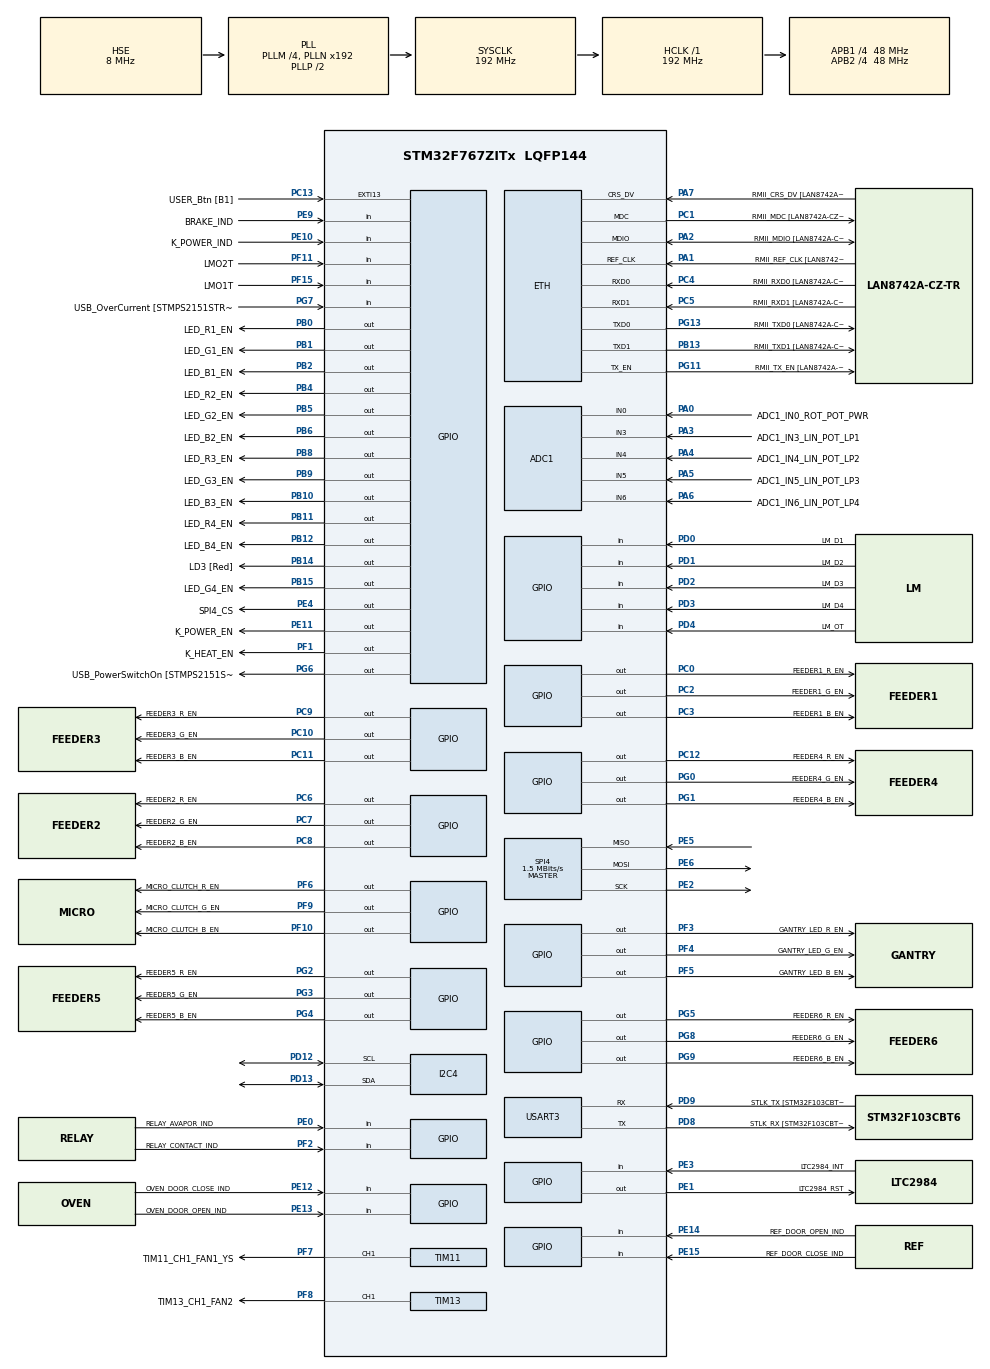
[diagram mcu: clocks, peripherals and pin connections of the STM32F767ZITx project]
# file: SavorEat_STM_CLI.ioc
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ADC1.Channel-0\#ChannelRegularConversion=ADC_CHANNEL_0
ADC1.NbrOfConversionFlag=1
ADC1.Rank-0\#ChannelRegularConversion=1
ADC1.SamplingTime-0\#ChannelRegularConversion=ADC_SAMPLETIME_112CYCLES
ADC1.master=1
ETH.MediaInterface=HAL_ETH_RMII_MODE
ETH.PHY_Name=LAN8742A_PHY_ADDRESS
ETH.PHY_Value=0
ETH.PhyAddress=0
FREERTOS.Tasks01=defaultTask,0,2048,StartDefaultTask,Default,NULL,Dynamic,NULL,NULL
FREERTOS.configTOTAL_HEAP_SIZE=0x20000
FREERTOS.configUSE_NEWLIB_REENTRANT=1
I2C4.Timing=0x20303E5D
LWIP.BSP.number=1
LWIP.GATEWAY_ADDRESS=010.001.001.001
LWIP.IP_ADDRESS=010.001.001.020
LWIP.LWIP_DHCP=0
LWIP.LWIP_MPU_COMPATIBLE=0
LWIP.NETMASK_ADDRESS=255.255.255.000
LWIP.Version=v2.1.2_Cube
LWIP0.BSP.STBoard=false
LWIP0.BSP.api=BSP_COMPONENT_DRIVER
LWIP0.BSP.component=LAN8742
LWIP0.BSP.instance=LAN8742
LWIP0.BSP.name=Driver_PHY
LWIP0.BSP.semaphore=S_LAN8742
LWIP0.BSP.solution=LAN8742
Mcu.Family=STM32F7
Mcu.Name=STM32F767ZITx
Mcu.Package=LQFP144
NVIC.ETH_IRQn=true\:5\:0\:false\:false\:true\:true\:false\:true\:true
NVIC.EXTI15_10_IRQn=true\:5\:0\:false\:false\:true\:true\:true\:true\:true
NVIC.PriorityGroup=NVIC_PRIORITYGROUP_4
NVIC.TIM1_UP_TIM10_IRQn=true\:15\:0\:false\:false\:true\:false\:false\:true\:true
NVIC.TimeBase=TIM1_UP_TIM10_IRQn
NVIC.TimeBaseIP=TIM10
PA0/WKUP.GPIO_Label=ADC1_IN0_ROT_POT_PWR
PA0/WKUP.Signal=ADCx_IN0
PA1.GPIO_Label=RMII_REF_CLK [LAN8742A-CZ-TR_REFCLK0]
PA1.Mode=RMII
PA1.Signal=ETH_REF_CLK
PA10.GPIO_Label=USB_ID
PA10.Signal=USB_OTG_FS_ID
PA11.GPIO_Label=USB_DM
PA11.Signal=USB_OTG_FS_DM
PA12.GPIO_Label=USB_DP
PA12.Signal=USB_OTG_FS_DP
PA13.GPIO_Label=TMS
PA13.Mode=Trace_Asynchronous_SW
PA13.Signal=SYS_JTMS-SWDIO
PA14.GPIO_Label=TCK
PA14.Mode=Trace_Asynchronous_SW
PA14.Signal=SYS_JTCK-SWCLK
PA2.GPIO_Label=RMII_MDIO [LAN8742A-CZ-TR_MDIO]
PA2.Mode=RMII
PA2.Signal=ETH_MDIO
PA3.GPIO_Label=ADC1_IN3_LIN_POT_LP1
PA3.Signal=ADCx_IN3
PA4.GPIO_Label=ADC1_IN4_LIN_POT_LP2
PA4.Signal=ADCx_IN4
PA5.GPIO_Label=ADC1_IN5_LIN_POT_LP3
PA5.Signal=ADCx_IN5
PA6.GPIO_Label=ADC1_IN6_LIN_POT_LP4
PA6.Signal=ADCx_IN6
PA7.GPIO_Label=RMII_CRS_DV [LAN8742A-CZ-TR_CRS_DV]
PA7.Mode=RMII
PA7.Signal=ETH_CRS_DV
PA8.GPIO_Label=USB_SOF [TP1]
PA8.Signal=USB_OTG_FS_SOF
PA9.GPIO_Label=USB_VBUS
PA9.Signal=USB_OTG_FS_VBUS
PB0.GPIO_Label=LED_R1_EN
PB0.Signal=GPIO_Output
PB1.GPIO_Label=LED_G1_EN
PB1.Signal=GPIO_Output
PB10.GPIO_Label=LED_B3_EN
PB10.Signal=GPIO_Output
PB11.GPIO_Label=LED_R4_EN
PB11.Signal=GPIO_Output
PB12.GPIO_Label=LED_B4_EN
PB12.Signal=GPIO_Output
PB13.GPIO_Label=RMII_TXD1 [LAN8742A-CZ-TR_TXD1]
PB13.Mode=RMII
PB13.Signal=ETH_TXD1
PB14.GPIO_Label=LD3 [Red]
PB14.Signal=GPIO_Output
PB15.GPIO_Label=LED_G4_EN
PB15.Signal=GPIO_Output
PB2.GPIO_Label=LED_B1_EN
PB2.Signal=GPIO_Output
PB3.GPIO_Label=SWO
PB3.Mode=Trace_Asynchronous_SW
PB3.Signal=SYS_JTDO-SWO
PB4.GPIO_Label=LED_R2_EN
PB4.Signal=GPIO_Output
PB5.GPIO_Label=LED_G2_EN
PB5.Signal=GPIO_Output
PB6.GPIO_Label=LED_B2_EN
PB6.Signal=GPIO_Output
PB8.GPIO_Label=LED_R3_EN
PB8.Signal=GPIO_Output
PB9.GPIO_Label=LED_G3_EN
PB9.Signal=GPIO_Output
PC0.GPIO_Label=FEEDER1_R_EN
PC0.Signal=GPIO_Output
PC1.GPIO_Label=RMII_MDC [LAN8742A-CZ-TR_MDC]
PC1.Mode=RMII
PC1.Signal=ETH_MDC
PC10.GPIO_Label=FEEDER3_G_EN
PC10.Signal=GPIO_Output
PC11.GPIO_Label=FEEDER3_B_EN
PC11.Signal=GPIO_Output
PC12.GPIO_Label=FEEDER4_R_EN
PC12.Signal=GPIO_Output
PC13.GPIO_Label=USER_Btn [B1]
PC13.Signal=GPXTI13
PC14/OSC32_IN.Mode=LSE-External-Oscillator
PC14/OSC32_IN.Signal=RCC_OSC32_IN
PC15/OSC32_OUT.Mode=LSE-External-Oscillator
PC15/OSC32_OUT.Signal=RCC_OSC32_OUT
PC2.GPIO_Label=FEEDER1_G_EN
PC2.Signal=GPIO_Output
PC3.GPIO_Label=FEEDER1_B_EN
PC3.Signal=GPIO_Output
PC4.GPIO_Label=RMII_RXD0 [LAN8742A-CZ-TR_RXD0]
PC4.Mode=RMII
PC4.Signal=ETH_RXD0
PC5.GPIO_Label=RMII_RXD1 [LAN8742A-CZ-TR_RXD1]
PC5.Mode=RMII
PC5.Signal=ETH_RXD1
PC6.GPIO_Label=FEEDER2_R_EN
PC6.Signal=GPIO_Output
PC7.GPIO_Label=FEEDER2_G_EN
PC7.Signal=GPIO_Output
PC8.GPIO_Label=FEEDER2_B_EN
PC8.Signal=GPIO_Output
PC9.GPIO_Label=FEEDER3_R_EN
PC9.Signal=GPIO_Output
PD0.GPIO_Label=LM_D1
PD0.Signal=GPIO_Input
PD1.GPIO_Label=LM_D2
PD1.Signal=GPIO_Input
PD12.Mode=I2C
PD12.Signal=I2C4_SCL
PD13.Mode=I2C
PD13.Signal=I2C4_SDA
PD2.GPIO_Label=LM_D3
PD2.Signal=GPIO_Input
PD3.GPIO_Label=LM_D4
PD3.Signal=GPIO_Input
PD4.GPIO_Label=LM_OT
PD4.Signal=GPIO_Input
PD8.GPIO_Label=STLK_RX [STM32F103CBT6_PA3]
PD8.Mode=Asynchronous
PD8.Signal=USART3_TX
PD9.GPIO_Label=STLK_TX [STM32F103CBT6_PA2]
PD9.Mode=Asynchronous
PD9.Signal=USART3_RX
PE0.GPIO_Label=RELAY_AVAPOR_IND
PE0.Signal=GPIO_Input
PE1.GPIO_Label=LTC2984_RST
PE1.PinState=GPIO_PIN_SET
PE1.Signal=GPIO_Output
PE10.GPIO_Label=K_POWER_IND
PE10.Signal=GPIO_Input
PE11.GPIO_Label=K_POWER_EN
PE11.Signal=GPIO_Output
PE12.GPIO_Label=OVEN_DOOR_CLOSE_IND
PE12.Signal=GPIO_Input
PE13.GPIO_Label=OVEN_DOOR_OPEN_IND
PE13.Signal=GPIO_Input
PE14.GPIO_Label=REF_DOOR_OPEN_IND
PE14.Signal=GPIO_Input
PE15.GPIO_Label=REF_DOOR_CLOSE_IND
PE15.Signal=GPIO_Input
PE2.Mode=Full_Duplex_Master
PE2.Signal=SPI4_SCK
PE3.GPIO_Label=LTC2984_INT
PE3.Signal=GPIO_Input
PE4.GPIO_Label=SPI4_CS
PE4.GPIO_Speed=GPIO_SPEED_FREQ_VERY_HIGH
PE4.PinState=GPIO_PIN_SET
PE4.Signal=GPIO_Output
PE5.Mode=Full_Duplex_Master
PE5.Signal=SPI4_MISO
PE6.Mode=Full_Duplex_Master
PE6.Signal=SPI4_MOSI
PE9.GPIO_Label=BRAKE_IND
PE9.Signal=GPIO_Input
PF1.GPIO_Label=K_HEAT_EN
PF1.Signal=GPIO_Output
PF10.GPIO_Label=MICRO_CLUTCH_B_EN
PF10.Signal=GPIO_Output
PF11.GPIO_Label=LMO2T
PF11.Signal=GPIO_Input
PF15.GPIO_Label=LMO1T
PF15.Signal=GPIO_Input
PF2.GPIO_Label=RELAY_CONTACT_IND
PF2.Signal=GPIO_Input
PF3.GPIO_Label=GANTRY_LED_R_EN
PF3.Signal=GPIO_Output
PF4.GPIO_Label=GANTRY_LED_G_EN
PF4.Signal=GPIO_Output
PF5.GPIO_Label=GANTRY_LED_B_EN
PF5.Signal=GPIO_Output
PF6.GPIO_Label=MICRO_CLUTCH_R_EN
PF6.Signal=GPIO_Output
PF7.GPIO_Label=TIM11_CH1_FAN1_YS
PF7.Signal=S_TIM11_CH1
PF8.GPIO_Label=TIM13_CH1_FAN2
PF8.Signal=S_TIM13_CH1
PF9.GPIO_Label=MICRO_CLUTCH_G_EN
PF9.Signal=GPIO_Output
PG0.GPIO_Label=FEEDER4_G_EN
PG0.Signal=GPIO_Output
PG1.GPIO_Label=FEEDER4_B_EN
PG1.Signal=GPIO_Output
PG11.GPIO_Label=RMII_TX_EN [LAN8742A-CZ-TR_TXEN]
PG11.Mode=RMII
PG11.Signal=ETH_TX_EN
PG13.GPIO_Label=RMII_TXD0 [LAN8742A-CZ-TR_TXD0]
PG13.Mode=RMII
PG13.Signal=ETH_TXD0
PG2.GPIO_Label=FEEDER5_R_EN
PG2.Signal=GPIO_Output
PG3.GPIO_Label=FEEDER5_G_EN
PG3.Signal=GPIO_Output
PG4.GPIO_Label=FEEDER5_B_EN
PG4.Signal=GPIO_Output
PG5.GPIO_Label=FEEDER6_R_EN
PG5.Signal=GPIO_Output
PG6.GPIO_Label=USB_PowerSwitchOn [STMPS2151STR_EN]
PG6.Signal=GPIO_Output
PG7.GPIO_Label=USB_OverCurrent [STMPS2151STR_FAULT]
PG7.Signal=GPIO_Input
PG8.GPIO_Label=FEEDER6_G_EN
PG8.Signal=GPIO_Output
PG9.GPIO_Label=FEEDER6_B_EN 
PG9.Signal=GPIO_Output
PH0/OSC_IN.GPIO_Label=MCO [STM32F103CBT6_PA8]
PH0/OSC_IN.Mode=HSE-External-Oscillator
PH0/OSC_IN.Signal=RCC_OSC_IN
PH1/OSC_OUT.Mode=HSE-External-Oscillator
PH1/OSC_OUT.Signal=RCC_OSC_OUT
ProjectManager.HeapSize=0x200
ProjectManager.StackSize=0x400
ProjectManager.TargetToolchain=STM32CubeIDE
RCC.48MHZClocksFreq_Value=24000000
RCC.AHBFreq_Value=192000000
RCC.APB1CLKDivider=RCC_HCLK_DIV4
RCC.APB1Freq_Value=48000000
RCC.APB1TimFreq_Value=96000000
RCC.APB2CLKDivider=RCC_HCLK_DIV4
RCC.APB2Freq_Value=48000000
RCC.APB2TimFreq_Value=96000000
RCC.CortexFreq_Value=192000000
RCC.HCLKFreq_Value=192000000
RCC.HSE_VALUE=8000000
RCC.HSI_VALUE=16000000
RCC.PLLM=4
RCC.PLLMUL=RCC_PLL_MUL9
RCC.PLLQ=8
RCC.PLLSourceVirtual=RCC_PLLSOURCE_HSE
RCC.PRESCALERUSB=RCC_USBCLKSOURCE_PLL_DIV1_5
RCC.SYSCLKFreq_VALUE=192000000
RCC.SYSCLKSource=RCC_SYSCLKSOURCE_PLLCLK
RCC.SYSCLKSourceVirtual=RCC_SYSCLKSOURCE_PLLCLK
RCC.USBFreq_Value=48000000
RCC.VCOOutputFreq_Value=384000000
SH.ADCx_IN0.0=ADC1_IN0,IN0
SH.ADCx_IN3.0=ADC1_IN3,IN3
SH.ADCx_IN4.0=ADC1_IN4,IN4
SH.ADCx_IN5.0=ADC1_IN5,IN5
SH.ADCx_IN6.0=ADC1_IN6,IN6
SH.S_TIM11_CH1.0=TIM11_CH1,PWM Generation1 CH1
SH.S_TIM13_CH1.0=TIM13_CH1,PWM Generation1 CH1
SPI4.BaudRatePrescaler=SPI_BAUDRATEPRESCALER_32
SPI4.CLKPolarity=SPI_POLARITY_LOW
SPI4.CalculateBaudRate=1.5 MBits/s
SPI4.DataSize=SPI_DATASIZE_8BIT
SPI4.Direction=SPI_DIRECTION_2LINES
SPI4.Mode=SPI_MODE_MASTER
SPI4.VirtualType=VM_MASTER
TIM11.AutoReloadPreload=TIM_AUTORELOAD_PRELOAD_ENABLE
TIM11.Channel=TIM_CHANNEL_1
TIM11.Period=100-1
TIM11.Prescaler=40-1
TIM11.Pulse=20
TIM13.AutoReloadPreload=TIM_AUTORELOAD_PRELOAD_ENABLE
TIM13.Channel=TIM_CHANNEL_1
TIM13.Period=100-1
TIM13.Prescaler=9600-1
TIM13.Pulse=20
USART3.VirtualMode-Asynchronous=VM_ASYNC
VP_FREERTOS_VS_CMSIS_V1.Mode=CMSIS_V1
VP_LWIP_VS_Enabled.Mode=Enabled
VP_SYS_VS_tim10.Mode=TIM10
VP_TIM11_VS_ClockSourceINT.Mode=Enable_Timer
VP_TIM13_VS_ClockSourceINT.Mode=Enable_Timer
board=NUCLEO-F767ZI

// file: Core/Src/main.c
/* USER CODE BEGIN Header */
/**
  ******************************************************************************
  * @file           : main.c
  * @brief          : Main program body
  ******************************************************************************
  * @attention
  *
  * Copyright (c) 2023 STMicroelectronics.
  * All rights reserved.
  *
  * This software is licensed under terms that can be found in the LICENSE file
  * in the root directory of this software component.
  * If no LICENSE file comes with this software, it is provided AS-IS.
  *
  ******************************************************************************
  */
/* USER CODE END Header */
#include "main.h"
#include "cmsis_os.h"
#include "lwip.h"

/* USER CODE BEGIN Includes */
#include <stdio.h>
#include "Utils.h"
#include "Main_Task_Mgr.h"
#include "Syslog_Mgr.h"
#include "CLI_Mgr.h"
/* USER CODE END Includes */

ADC_HandleTypeDef hadc1;

I2C_HandleTypeDef hi2c4;

SPI_HandleTypeDef hspi4;

TIM_HandleTypeDef htim11;
TIM_HandleTypeDef htim13;

UART_HandleTypeDef huart3;

osThreadId defaultTaskHandle;

void SystemClock_Config(void);
static void MX_GPIO_Init(void);
static void MX_USART3_UART_Init(void);
static void MX_ADC1_Init(void);
static void MX_I2C4_Init(void);
static void MX_SPI4_Init(void);
static void MX_TIM11_Init(void);
static void MX_TIM13_Init(void);
void StartDefaultTask(void const * argument);

int main(void)
{

  /* MCU Configuration--------------------------------------------------------*/

  /* Reset of all peripherals, Initializes the Flash interface and the Systick. */
  HAL_Init();

  /* Configure the system clock */
  SystemClock_Config();

  /* Initialize all configured peripherals */
  MX_GPIO_Init();
  MX_USART3_UART_Init();
  MX_ADC1_Init();
  MX_I2C4_Init();
  MX_SPI4_Init();
  MX_TIM11_Init();
  MX_TIM13_Init();

  /* USER CODE BEGIN RTOS_QUEUES */
  /* add queues, ... */
  if( Main_Task_Mgr_Syslog_Queue_Init() )
  {
  	  //TBD error
  }

  /* USER CODE END RTOS_QUEUES */

  /* Create the thread(s) */
  /* definition and creation of defaultTask */
  osThreadDef(defaultTask, StartDefaultTask, osPriorityNormal, 0, 2048);
  defaultTaskHandle = osThreadCreate(osThread(defaultTask), NULL);

  /* USER CODE BEGIN RTOS_THREADS */
  /* add threads, ... */
  if( Syslog_Mgr_Thread_Init() )
  {
	  //TBD Error
  }

  /* USER CODE END RTOS_THREADS */

  /* Start scheduler */
  osKernelStart();

  /* We should never get here as control is now taken by the scheduler */
  /* Infinite loop */
  while (1)
  {

  }
}

void SystemClock_Config(void)
{
  RCC_OscInitTypeDef RCC_OscInitStruct = {0};
  RCC_ClkInitTypeDef RCC_ClkInitStruct = {0};

  /** Configure LSE Drive Capability
  */
  HAL_PWR_EnableBkUpAccess();

  /** Configure the main internal regulator output voltage
  */
  __HAL_RCC_PWR_CLK_ENABLE();
  __HAL_PWR_VOLTAGESCALING_CONFIG(PWR_REGULATOR_VOLTAGE_SCALE1);

  /** Initializes the RCC Oscillators according to the specified parameters
  * in the RCC_OscInitTypeDef structure.
  */
  RCC_OscInitStruct.OscillatorType = RCC_OSCILLATORTYPE_HSE;
  RCC_OscInitStruct.HSEState = RCC_HSE_ON;
  RCC_OscInitStruct.PLL.PLLState = RCC_PLL_ON;
  RCC_OscInitStruct.PLL.PLLSource = RCC_PLLSOURCE_HSE;
  RCC_OscInitStruct.PLL.PLLM = 4;
  RCC_OscInitStruct.PLL.PLLN = 192;
  RCC_OscInitStruct.PLL.PLLP = RCC_PLLP_DIV2;
  RCC_OscInitStruct.PLL.PLLQ = 8;
  RCC_OscInitStruct.PLL.PLLR = 2;
  if (HAL_RCC_OscConfig(&RCC_OscInitStruct) != HAL_OK)
  {
    Error_Handler();
  }

  /** Activate the Over-Drive mode
  */
  if (HAL_PWREx_EnableOverDrive() != HAL_OK)
  {
    Error_Handler();
  }

  /** Initializes the CPU, AHB and APB buses clocks
  */
  RCC_ClkInitStruct.ClockType = RCC_CLOCKTYPE_HCLK|RCC_CLOCKTYPE_SYSCLK
                              |RCC_CLOCKTYPE_PCLK1|RCC_CLOCKTYPE_PCLK2;
  RCC_ClkInitStruct.SYSCLKSource = RCC_SYSCLKSOURCE_PLLCLK;
  RCC_ClkInitStruct.AHBCLKDivider = RCC_SYSCLK_DIV1;
  RCC_ClkInitStruct.APB1CLKDivider = RCC_HCLK_DIV4;
  RCC_ClkInitStruct.APB2CLKDivider = RCC_HCLK_DIV4;

  if (HAL_RCC_ClockConfig(&RCC_ClkInitStruct, FLASH_LATENCY_6) != HAL_OK)
  {
    Error_Handler();
  }
}

static void MX_ADC1_Init(void)
{

  ADC_ChannelConfTypeDef sConfig = {0};

  /** Configure the global features of the ADC (Clock, Resolution, Data Alignment and number of conversion)
  */
  hadc1.Instance = ADC1;
  hadc1.Init.ClockPrescaler = ADC_CLOCK_SYNC_PCLK_DIV2;
  hadc1.Init.Resolution = ADC_RESOLUTION_12B;
  hadc1.Init.ScanConvMode = ADC_SCAN_DISABLE;
  hadc1.Init.ContinuousConvMode = DISABLE;
  hadc1.Init.DiscontinuousConvMode = DISABLE;
  hadc1.Init.ExternalTrigConvEdge = ADC_EXTERNALTRIGCONVEDGE_NONE;
  hadc1.Init.ExternalTrigConv = ADC_SOFTWARE_START;
  hadc1.Init.DataAlign = ADC_DATAALIGN_RIGHT;
  hadc1.Init.NbrOfConversion = 1;
  hadc1.Init.DMAContinuousRequests = DISABLE;
  hadc1.Init.EOCSelection = ADC_EOC_SINGLE_CONV;
  if (HAL_ADC_Init(&hadc1) != HAL_OK)
  {
    Error_Handler();
  }

  /** Configure for the selected ADC regular channel its corresponding rank in the sequencer and its sample time.
  */
  sConfig.Channel = ADC_CHANNEL_0;
  sConfig.Rank = ADC_REGULAR_RANK_1;
  sConfig.SamplingTime = ADC_SAMPLETIME_112CYCLES;
  if (HAL_ADC_ConfigChannel(&hadc1, &sConfig) != HAL_OK)
  {
    Error_Handler();
  }

}

static void MX_I2C4_Init(void)
{

  hi2c4.Instance = I2C4;
  hi2c4.Init.Timing = 0x20303E5D;
  hi2c4.Init.OwnAddress1 = 0;
  hi2c4.Init.AddressingMode = I2C_ADDRESSINGMODE_7BIT;
  hi2c4.Init.DualAddressMode = I2C_DUALADDRESS_DISABLE;
  hi2c4.Init.OwnAddress2 = 0;
  hi2c4.Init.OwnAddress2Masks = I2C_OA2_NOMASK;
  hi2c4.Init.GeneralCallMode = I2C_GENERALCALL_DISABLE;
  hi2c4.Init.NoStretchMode = I2C_NOSTRETCH_DISABLE;
  if (HAL_I2C_Init(&hi2c4) != HAL_OK)
  {
    Error_Handler();
  }

  /** Configure Analogue filter
  */
  if (HAL_I2CEx_ConfigAnalogFilter(&hi2c4, I2C_ANALOGFILTER_ENABLE) != HAL_OK)
  {
    Error_Handler();
  }

  /** Configure Digital filter
  */
  if (HAL_I2CEx_ConfigDigitalFilter(&hi2c4, 0) != HAL_OK)
  {
    Error_Handler();
  }

}

static void MX_SPI4_Init(void)
{

  /* SPI4 parameter configuration*/
  hspi4.Instance = SPI4;
  hspi4.Init.Mode = SPI_MODE_MASTER;
  hspi4.Init.Direction = SPI_DIRECTION_2LINES;
  hspi4.Init.DataSize = SPI_DATASIZE_8BIT;
  hspi4.Init.CLKPolarity = SPI_POLARITY_LOW;
  hspi4.Init.CLKPhase = SPI_PHASE_1EDGE;
  hspi4.Init.NSS = SPI_NSS_SOFT;
  hspi4.Init.BaudRatePrescaler = SPI_BAUDRATEPRESCALER_32;
  hspi4.Init.FirstBit = SPI_FIRSTBIT_MSB;
  hspi4.Init.TIMode = SPI_TIMODE_DISABLE;
  hspi4.Init.CRCCalculation = SPI_CRCCALCULATION_DISABLE;
  hspi4.Init.CRCPolynomial = 7;
  hspi4.Init.CRCLength = SPI_CRC_LENGTH_DATASIZE;
  hspi4.Init.NSSPMode = SPI_NSS_PULSE_ENABLE;
  if (HAL_SPI_Init(&hspi4) != HAL_OK)
  {
    Error_Handler();
  }

}

static void MX_TIM11_Init(void)
{

  TIM_OC_InitTypeDef sConfigOC = {0};

  htim11.Instance = TIM11;
  htim11.Init.Prescaler = 40-1;
  htim11.Init.CounterMode = TIM_COUNTERMODE_UP;
  htim11.Init.Period = 100-1;
  htim11.Init.ClockDivision = TIM_CLOCKDIVISION_DIV1;
  htim11.Init.AutoReloadPreload = TIM_AUTORELOAD_PRELOAD_ENABLE;
  if (HAL_TIM_Base_Init(&htim11) != HAL_OK)
  {
    Error_Handler();
  }
  if (HAL_TIM_PWM_Init(&htim11) != HAL_OK)
  {
    Error_Handler();
  }
  sConfigOC.OCMode = TIM_OCMODE_PWM1;
  sConfigOC.Pulse = 20;
  sConfigOC.OCPolarity = TIM_OCPOLARITY_HIGH;
  sConfigOC.OCFastMode = TIM_OCFAST_DISABLE;
  if (HAL_TIM_PWM_ConfigChannel(&htim11, &sConfigOC, TIM_CHANNEL_1) != HAL_OK)
  {
    Error_Handler();
  }
  HAL_TIM_MspPostInit(&htim11);

}

static void MX_TIM13_Init(void)
{

  TIM_OC_InitTypeDef sConfigOC = {0};

  htim13.Instance = TIM13;
  htim13.Init.Prescaler = 9600-1;
  htim13.Init.CounterMode = TIM_COUNTERMODE_UP;
  htim13.Init.Period = 100-1;
  htim13.Init.ClockDivision = TIM_CLOCKDIVISION_DIV1;
  htim13.Init.AutoReloadPreload = TIM_AUTORELOAD_PRELOAD_ENABLE;
  if (HAL_TIM_Base_Init(&htim13) != HAL_OK)
  {
    Error_Handler();
  }
  if (HAL_TIM_PWM_Init(&htim13) != HAL_OK)
  {
    Error_Handler();
  }
  sConfigOC.OCMode = TIM_OCMODE_PWM1;
  sConfigOC.Pulse = 20;
  sConfigOC.OCPolarity = TIM_OCPOLARITY_HIGH;
  sConfigOC.OCFastMode = TIM_OCFAST_DISABLE;
  if (HAL_TIM_PWM_ConfigChannel(&htim13, &sConfigOC, TIM_CHANNEL_1) != HAL_OK)
  {
    Error_Handler();
  }
  HAL_TIM_MspPostInit(&htim13);

}

static void MX_USART3_UART_Init(void)
{

  huart3.Instance = USART3;
  huart3.Init.BaudRate = 115200;
  huart3.Init.WordLength = UART_WORDLENGTH_8B;
  huart3.Init.StopBits = UART_STOPBITS_1;
  huart3.Init.Parity = UART_PARITY_NONE;
  huart3.Init.Mode = UART_MODE_TX_RX;
  huart3.Init.HwFlowCtl = UART_HWCONTROL_NONE;
  huart3.Init.OverSampling = UART_OVERSAMPLING_16;
  huart3.Init.OneBitSampling = UART_ONE_BIT_SAMPLE_DISABLE;
  huart3.AdvancedInit.AdvFeatureInit = UART_ADVFEATURE_NO_INIT;
  if (HAL_UART_Init(&huart3) != HAL_OK)
  {
    Error_Handler();
  }

}

static void MX_GPIO_Init(void)
{
  GPIO_InitTypeDef GPIO_InitStruct = {0};

  /* GPIO Ports Clock Enable */
  __HAL_RCC_GPIOE_CLK_ENABLE();
  __HAL_RCC_GPIOC_CLK_ENABLE();
  __HAL_RCC_GPIOF_CLK_ENABLE();
  __HAL_RCC_GPIOH_CLK_ENABLE();
  __HAL_RCC_GPIOA_CLK_ENABLE();
  __HAL_RCC_GPIOB_CLK_ENABLE();
  __HAL_RCC_GPIOG_CLK_ENABLE();
  __HAL_RCC_GPIOD_CLK_ENABLE();

  /*Configure GPIO pin Output Level */
  HAL_GPIO_WritePin(GPIOE, SPI4_CS_Pin|LTC2984_RST_Pin, GPIO_PIN_SET);

  /*Configure GPIO pin Output Level */
  HAL_GPIO_WritePin(GPIOF, K_HEAT_EN_Pin|GANTRY_LED_R_EN_Pin|GANTRY_LED_G_EN_Pin|GANTRY_LED_B_EN_Pin
                          |MICRO_CLUTCH_R_EN_Pin|MICRO_CLUTCH_G_EN_Pin|MICRO_CLUTCH_B_EN_Pin, GPIO_PIN_RESET);

  /*Configure GPIO pin Output Level */
  HAL_GPIO_WritePin(GPIOC, FEEDER1_R_EN_Pin|FEEDER1_G_EN_Pin|FEEDER1_B_EN_Pin|FEEDER2_R_EN_Pin
                          |FEEDER2_G_EN_Pin|FEEDER2_B_EN_Pin|FEEDER3_R_EN_Pin|FEEDER3_G_EN_Pin
                          |FEEDER3_B_EN_Pin|FEEDER4_R_EN_Pin, GPIO_PIN_RESET);

  /*Configure GPIO pin Output Level */
  HAL_GPIO_WritePin(GPIOB, LED_R1_EN_Pin|LED_G1_EN_Pin|LED_B1_EN_Pin|LED_B3_EN_Pin
                          |LED_R4_EN_Pin|LED_B4_EN_Pin|LD3_Pin|LED_G4_EN_Pin
                          |LED_R2_EN_Pin|LED_G2_EN_Pin|LED_B2_EN_Pin|LED_R3_EN_Pin
                          |LED_G3_EN_Pin, GPIO_PIN_RESET);

  /*Configure GPIO pin Output Level */
  HAL_GPIO_WritePin(GPIOG, FEEDER4_G_EN_Pin|FEEDER4_B_EN_Pin|FEEDER5_R_EN_Pin|FEEDER5_G_EN_Pin
                          |FEEDER5_B_EN_Pin|FEEDER6_R_EN_Pin|USB_PowerSwitchOn_Pin|FEEDER6_G_EN_Pin
                          |FEEDER6_B_EN_Pin, GPIO_PIN_RESET);

  /*Configure GPIO pin Output Level */
  HAL_GPIO_WritePin(K_POWER_EN_GPIO_Port, K_POWER_EN_Pin, GPIO_PIN_RESET);

  /*Configure GPIO pins : LTC2984_INT_Pin BRAKE_IND_Pin K_POWER_IND_Pin OVEN_DOOR_CLOSE_IND_Pin
                           OVEN_DOOR_OPEN_IND_Pin REF_DOOR_OPEN_IND_Pin REF_DOOR_CLOSE_IND_Pin RELAY_AVAPOR_IND_Pin */
  GPIO_InitStruct.Pin = LTC2984_INT_Pin|BRAKE_IND_Pin|K_POWER_IND_Pin|OVEN_DOOR_CLOSE_IND_Pin
                          |OVEN_DOOR_OPEN_IND_Pin|REF_DOOR_OPEN_IND_Pin|REF_DOOR_CLOSE_IND_Pin|RELAY_AVAPOR_IND_Pin;
  GPIO_InitStruct.Mode = GPIO_MODE_INPUT;
  GPIO_InitStruct.Pull = GPIO_NOPULL;
  HAL_GPIO_Init(GPIOE, &GPIO_InitStruct);

  /*Configure GPIO pin : SPI4_CS_Pin */
  GPIO_InitStruct.Pin = SPI4_CS_Pin;
  GPIO_InitStruct.Mode = GPIO_MODE_OUTPUT_PP;
  GPIO_InitStruct.Pull = GPIO_NOPULL;
  GPIO_InitStruct.Speed = GPIO_SPEED_FREQ_VERY_HIGH;
  HAL_GPIO_Init(SPI4_CS_GPIO_Port, &GPIO_InitStruct);

  /*Configure GPIO pin : USER_Btn_Pin */
  GPIO_InitStruct.Pin = USER_Btn_Pin;
  GPIO_InitStruct.Mode = GPIO_MODE_IT_RISING;
  GPIO_InitStruct.Pull = GPIO_NOPULL;
  HAL_GPIO_Init(USER_Btn_GPIO_Port, &GPIO_InitStruct);

  /*Configure GPIO pins : K_HEAT_EN_Pin GANTRY_LED_R_EN_Pin GANTRY_LED_G_EN_Pin GANTRY_LED_B_EN_Pin
                           MICRO_CLUTCH_R_EN_Pin MICRO_CLUTCH_G_EN_Pin MICRO_CLUTCH_B_EN_Pin */
  GPIO_InitStruct.Pin = K_HEAT_EN_Pin|GANTRY_LED_R_EN_Pin|GANTRY_LED_G_EN_Pin|GANTRY_LED_B_EN_Pin
                          |MICRO_CLUTCH_R_EN_Pin|MICRO_CLUTCH_G_EN_Pin|MICRO_CLUTCH_B_EN_Pin;
  GPIO_InitStruct.Mode = GPIO_MODE_OUTPUT_PP;
  GPIO_InitStruct.Pull = GPIO_NOPULL;
  GPIO_InitStruct.Speed = GPIO_SPEED_FREQ_LOW;
  HAL_GPIO_Init(GPIOF, &GPIO_InitStruct);

  /*Configure GPIO pins : RELAY_CONTACT_IND_Pin LMO2T_Pin LMO1T_Pin */
  GPIO_InitStruct.Pin = RELAY_CONTACT_IND_Pin|LMO2T_Pin|LMO1T_Pin;
  GPIO_InitStruct.Mode = GPIO_MODE_INPUT;
  GPIO_InitStruct.Pull = GPIO_NOPULL;
  HAL_GPIO_Init(GPIOF, &GPIO_InitStruct);

  /*Configure GPIO pins : FEEDER1_R_EN_Pin FEEDER1_G_EN_Pin FEEDER1_B_EN_Pin FEEDER2_R_EN_Pin
                           FEEDER2_G_EN_Pin FEEDER2_B_EN_Pin FEEDER3_R_EN_Pin FEEDER3_G_EN_Pin
                           FEEDER3_B_EN_Pin FEEDER4_R_EN_Pin */
  GPIO_InitStruct.Pin = FEEDER1_R_EN_Pin|FEEDER1_G_EN_Pin|FEEDER1_B_EN_Pin|FEEDER2_R_EN_Pin
                          |FEEDER2_G_EN_Pin|FEEDER2_B_EN_Pin|FEEDER3_R_EN_Pin|FEEDER3_G_EN_Pin
                          |FEEDER3_B_EN_Pin|FEEDER4_R_EN_Pin;
  GPIO_InitStruct.Mode = GPIO_MODE_OUTPUT_PP;
  GPIO_InitStruct.Pull = GPIO_NOPULL;
  GPIO_InitStruct.Speed = GPIO_SPEED_FREQ_LOW;
  HAL_GPIO_Init(GPIOC, &GPIO_InitStruct);

  /*Configure GPIO pins : LED_R1_EN_Pin LED_G1_EN_Pin LED_B1_EN_Pin LED_B3_EN_Pin
                           LED_R4_EN_Pin LED_B4_EN_Pin LD3_Pin LED_G4_EN_Pin
                           LED_R2_EN_Pin LED_G2_EN_Pin LED_B2_EN_Pin LED_R3_EN_Pin
                           LED_G3_EN_Pin */
  GPIO_InitStruct.Pin = LED_R1_EN_Pin|LED_G1_EN_Pin|LED_B1_EN_Pin|LED_B3_EN_Pin
                          |LED_R4_EN_Pin|LED_B4_EN_Pin|LD3_Pin|LED_G4_EN_Pin
                          |LED_R2_EN_Pin|LED_G2_EN_Pin|LED_B2_EN_Pin|LED_R3_EN_Pin
                          |LED_G3_EN_Pin;
  GPIO_InitStruct.Mode = GPIO_MODE_OUTPUT_PP;
  GPIO_InitStruct.Pull = GPIO_NOPULL;
  GPIO_InitStruct.Speed = GPIO_SPEED_FREQ_LOW;
  HAL_GPIO_Init(GPIOB, &GPIO_InitStruct);

  /*Configure GPIO pins : FEEDER4_G_EN_Pin FEEDER4_B_EN_Pin FEEDER5_R_EN_Pin FEEDER5_G_EN_Pin
                           FEEDER5_B_EN_Pin FEEDER6_R_EN_Pin USB_PowerSwitchOn_Pin FEEDER6_G_EN_Pin
                           FEEDER6_B_EN_Pin */
  GPIO_InitStruct.Pin = FEEDER4_G_EN_Pin|FEEDER4_B_EN_Pin|FEEDER5_R_EN_Pin|FEEDER5_G_EN_Pin
                          |FEEDER5_B_EN_Pin|FEEDER6_R_EN_Pin|USB_PowerSwitchOn_Pin|FEEDER6_G_EN_Pin
                          |FEEDER6_B_EN_Pin;
  GPIO_InitStruct.Mode = GPIO_MODE_OUTPUT_PP;
  GPIO_InitStruct.Pull = GPIO_NOPULL;
  GPIO_InitStruct.Speed = GPIO_SPEED_FREQ_LOW;
  HAL_GPIO_Init(GPIOG, &GPIO_InitStruct);

  /*Configure GPIO pins : K_POWER_EN_Pin LTC2984_RST_Pin */
  GPIO_InitStruct.Pin = K_POWER_EN_Pin|LTC2984_RST_Pin;
  GPIO_InitStruct.Mode = GPIO_MODE_OUTPUT_PP;
  GPIO_InitStruct.Pull = GPIO_NOPULL;
  GPIO_InitStruct.Speed = GPIO_SPEED_FREQ_LOW;
  HAL_GPIO_Init(GPIOE, &GPIO_InitStruct);

  /*Configure GPIO pin : USB_OverCurrent_Pin */
  GPIO_InitStruct.Pin = USB_OverCurrent_Pin;
  GPIO_InitStruct.Mode = GPIO_MODE_INPUT;
  GPIO_InitStruct.Pull = GPIO_NOPULL;
  HAL_GPIO_Init(USB_OverCurrent_GPIO_Port, &GPIO_InitStruct);

  /*Configure GPIO pins : USB_SOF_Pin USB_ID_Pin USB_DM_Pin USB_DP_Pin */
  GPIO_InitStruct.Pin = USB_SOF_Pin|USB_ID_Pin|USB_DM_Pin|USB_DP_Pin;
  GPIO_InitStruct.Mode = GPIO_MODE_AF_PP;
  GPIO_InitStruct.Pull = GPIO_NOPULL;
  GPIO_InitStruct.Speed = GPIO_SPEED_FREQ_VERY_HIGH;
  GPIO_InitStruct.Alternate = GPIO_AF10_OTG_FS;
  HAL_GPIO_Init(GPIOA, &GPIO_InitStruct);

  /*Configure GPIO pin : USB_VBUS_Pin */
  GPIO_InitStruct.Pin = USB_VBUS_Pin;
  GPIO_InitStruct.Mode = GPIO_MODE_INPUT;
  GPIO_InitStruct.Pull = GPIO_NOPULL;
  HAL_GPIO_Init(USB_VBUS_GPIO_Port, &GPIO_InitStruct);

  /*Configure GPIO pins : LM_D1_Pin LM_D2_Pin LM_D3_Pin LM_D4_Pin
                           LM_OT_Pin */
  GPIO_InitStruct.Pin = LM_D1_Pin|LM_D2_Pin|LM_D3_Pin|LM_D4_Pin
                          |LM_OT_Pin;
  GPIO_InitStruct.Mode = GPIO_MODE_INPUT;
  GPIO_InitStruct.Pull = GPIO_NOPULL;
  HAL_GPIO_Init(GPIOD, &GPIO_InitStruct);

  /* EXTI interrupt init*/
  HAL_NVIC_SetPriority(EXTI15_10_IRQn, 5, 0);
  HAL_NVIC_EnableIRQ(EXTI15_10_IRQn);

}

/* USER CODE BEGIN 4 */

#if (defined(__GNUC__) && !defined(__CC_ARM))
#define PUTCHAR_PROTOTYPE int __io_putchar(int ch)
#define GETCHAR_PROTOTYPE int __io_getchar(void)
#else
#define PUTCHAR_PROTOTYPE int fputc(int ch, FILE *f)
#define GETCHAR_PROTOTYPE int fgetc(FILE *f)
#endif /* __GNUC__ */

/**
  * @brief  Retargets the C library printf function to the USART.
  * @param  None
  * @retval None
  */
PUTCHAR_PROTOTYPE
{
  /* Place your implementation of fputc here */
  /* e.g. write a character to the USART3 and Loop until the end of transmission */
  while ( HAL_OK != HAL_UART_Transmit( &huart3 , ( uint8_t * )&ch , 1 , 2 ) )
  {
    ;
  }
  return ch;
}

/**
  * @brief  Retargets the C library scanf function to the USART.
  * @param  None
  * @retval None
  */
GETCHAR_PROTOTYPE
{
  /* Place your implementation of fgetc here */
  /* e.g. read a character on USART3 and loop until the end of read */
  uint8_t ch = 0;
  while ( HAL_OK != HAL_UART_Receive( &huart3 , ( uint8_t * )&ch , 1 , 2 ) )
  {
    ;
  }
  return ch;
}

/* USER CODE END 4 */

void StartDefaultTask(void const * argument)
{
  /* init code for LWIP */
  MX_LWIP_Init();
  /* USER CODE BEGIN 5 */
	char 			ch;

	/* Infinite loop */
	while( 1 )
	{
		if( HAL_UART_Receive( &huart3 , (uint8_t *)&ch , 1 , 2 ) != HAL_OK )
		{
			CLI_Mgr_Handler( 0 );
		}
		else
		{
			CLI_Mgr_Handler( ch );
		}
		Main_Task_Mgr_Handler();
	}
  /* USER CODE END 5 */
}

void HAL_TIM_PeriodElapsedCallback(TIM_HandleTypeDef *htim)
{
  if (htim->Instance == TIM10) {
    HAL_IncTick();
  }
}

void Error_Handler(void)
{
  __disable_irq();
  while (1)
  {
  }
}
